VERSION ""

NS_ :

BS_:

BU_:

BO_ 849 Calibration_0: 8 Vector__XXX
 SG_ Tester_ForSASCalibrate : 7|8@0+ (1,0) [0|0] "" Vector__XXX

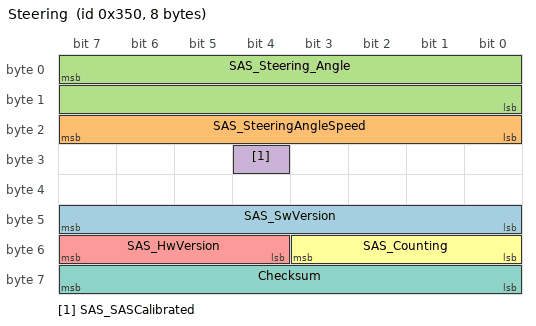
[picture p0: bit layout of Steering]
BO_ 848 Steering: 8 Vector__XXX
 SG_ SAS_SwVersion : 47|8@0+ (1,0) [0|255] "" Vector__XXX
 SG_ SAS_SteeringAngleSpeed : 23|8@0+ (4,0) [0|1020] "" Vector__XXX
 SG_ SAS_Steering_Angle : 7|16@0- (0.1,0) [-3276.8|3276.7] "" Vector__XXX
 SG_ SAS_SASCalibrated : 28|1@0+ (1,0) [0|1] "" Vector__XXX
 SG_ SAS_HwVersion : 52|4@1+ (1,0) [0|15] "" Vector__XXX
 SG_ SAS_Counting : 51|4@0+ (1,0) [0|15] "" Vector__XXX
 SG_ Checksum : 63|8@0+ (1,0) [0|255] "" Vector__XXX

CM_ SG_ 849 Tester_ForSASCalibrate "0x03:Request SAS Calibrate
0x05:Request SAS De-Calibrate
0x00:Default Other Byte";
BA_DEF_  "BusType" STRING ;
BA_DEF_DEF_  "BusType" "CAN";
